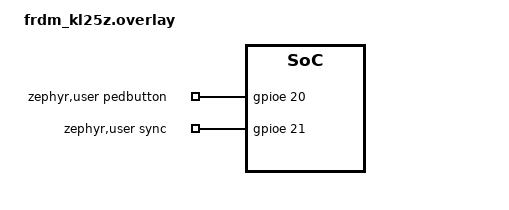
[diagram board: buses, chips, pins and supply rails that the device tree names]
/* Overlay para habilitar GPIOE e configurar GPIO do pedestre
 * Não edite o DTS gerado diretamente — este overlay altera o DT em time de build.
 */
/ {
    zephyr,user {
        pedbutton_gpios = <&gpioe 20 GPIO_ACTIVE_HIGH>;
        sync_gpios = <&gpioe 21 GPIO_ACTIVE_HIGH>;
    };
};

&gpioe {
    status = "okay";
};
